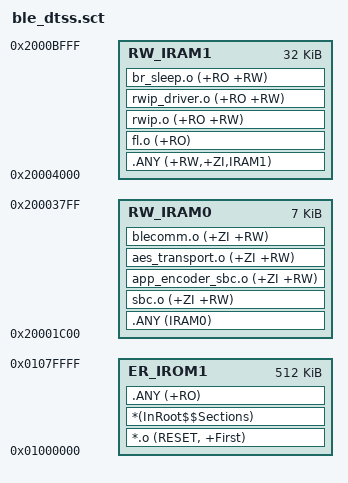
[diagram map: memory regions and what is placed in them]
; *************************************************************
; *** Scatter-Loading Description File generated by uVision ***
; *************************************************************

LR_IROM1 0x01000000 0x00080000    {    ; load region size_region
  ER_IROM1 0x01000000 0x00080000  {    ; load address = execution address
   *.o (RESET, +First)
   *(InRoot$$Sections)
   .ANY (+RO)
  }
  RW_IRAM0 0x20001C00 0x00001C00  {    ; RW data 0 (7 KB, mostly free — park large voice buffers here)
    .ANY (IRAM0)
    sbc.o (+ZI +RW)
    app_encoder_sbc.o (+ZI +RW)
    aes_transport.o (+ZI +RW)
    blecomm.o (+ZI +RW)
  }
  RW_IRAM1 0x20004000 0x00008000  {    ; RW data (32 KB)
   .ANY (+RW,+ZI,IRAM1)
   fl.o (+RO)
   rwip.o (+RO +RW)
   rwip_driver.o (+RO +RW)
   br_sleep.o (+RO +RW)
  }
}

